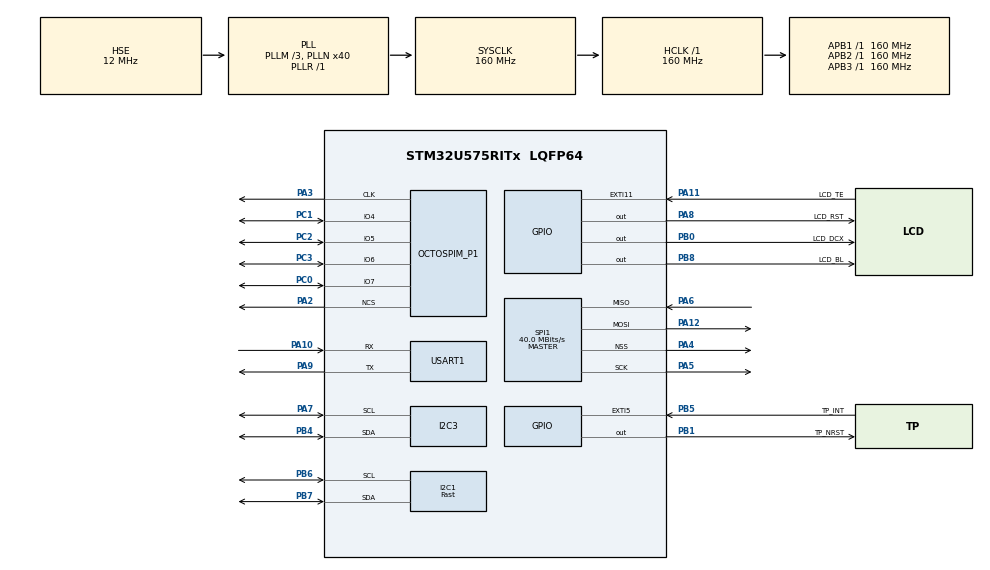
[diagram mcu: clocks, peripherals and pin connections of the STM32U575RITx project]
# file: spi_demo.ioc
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CORTEX_M33_NS.userName=CORTEX_M33
I2C1.I2C_Speed_Mode=I2C_Fast
I2C1.Timing=0x00F07BFF
I2C3.Timing=0x30909DEC
Mcu.Family=STM32U5
Mcu.Name=STM32U575RITx
Mcu.Package=LQFP64
NVIC.EXTI11_IRQn=true\:5\:0\:false\:false\:true\:true\:true\:true
NVIC.EXTI5_IRQn=true\:0\:0\:false\:false\:true\:true\:true\:true
NVIC.PriorityGroup=NVIC_PRIORITYGROUP_4
NVIC.TIM6_IRQn=true\:2\:0\:true\:false\:true\:false\:true\:true
NVIC.TimeBase=TIM6_IRQn
NVIC.TimeBaseIP=TIM6
PA10.Mode=Asynchronous
PA10.Signal=USART1_RX
PA11.GPIO_Label=LCD_TE
PA11.GPIO_ModeDefaultEXTI=GPIO_MODE_IT_FALLING
PA11.GPIO_PuPd=GPIO_PULLUP
PA11.Signal=GPXTI11
PA12.GPIO_Speed=GPIO_SPEED_FREQ_VERY_HIGH
PA12.Mode=Full_Duplex_Master
PA12.Signal=SPI1_MOSI
PA13\ (JTMS/SWDIO).Mode=Serial_Wire
PA13\ (JTMS/SWDIO).Signal=DEBUG_JTMS-SWDIO
PA14\ (JTCK/SWCLK).Mode=Serial_Wire
PA14\ (JTCK/SWCLK).Signal=DEBUG_JTCK-SWCLK
PA2.Mode=OCTOSPI1_Port1_NCS
PA2.Signal=OCTOSPIM_P1_NCS
PA3.Mode=O1_P1_CLK
PA3.Signal=OCTOSPIM_P1_CLK
PA4.Mode=NSS_Signal_Hard_Output
PA4.Signal=SPI1_NSS
PA5.GPIO_Speed=GPIO_SPEED_FREQ_VERY_HIGH
PA5.Mode=Full_Duplex_Master
PA5.Signal=SPI1_SCK
PA6.GPIO_Speed=GPIO_SPEED_FREQ_VERY_HIGH
PA6.Mode=Full_Duplex_Master
PA6.Signal=SPI1_MISO
PA7.Mode=I2C
PA7.Signal=I2C3_SCL
PA8.GPIO_Label=LCD_RST
PA8.Signal=GPIO_Output
PA9.Mode=Asynchronous
PA9.Signal=USART1_TX
PB0.GPIO_Label=LCD_DCX
PB0.Signal=GPIO_Output
PB1.GPIO_Label=TP_NRST
PB1.Signal=GPIO_Output
PB4\ (NJTRST).Mode=I2C
PB4\ (NJTRST).Signal=I2C3_SDA
PB5.GPIO_Label=TP_INT
PB5.GPIO_ModeDefaultEXTI=GPIO_MODE_IT_FALLING
PB5.GPIO_PuPd=GPIO_PULLUP
PB5.Signal=GPXTI5
PB6.Mode=I2C
PB6.Signal=I2C1_SCL
PB7.Mode=I2C
PB7.Signal=I2C1_SDA
PB8.GPIO_Label=LCD_BL
PB8.Signal=GPIO_Output
PC0.Mode=OCTOSPI1_IOL_Port1H
PC0.Signal=OCTOSPIM_P1_IO7
PC1.Mode=OCTOSPI1_IOL_Port1H
PC1.Signal=OCTOSPIM_P1_IO4
PC14-OSC32_IN\ (PC14).Mode=LSE-External-Oscillator-for-RTC
PC14-OSC32_IN\ (PC14).Signal=RCC_OSC32_IN
PC15-OSC32_OUT\ (PC15).Mode=LSE-External-Oscillator-for-RTC
PC15-OSC32_OUT\ (PC15).Signal=RCC_OSC32_OUT
PC2.Mode=OCTOSPI1_IOL_Port1H
PC2.Signal=OCTOSPIM_P1_IO5
PC3.Mode=OCTOSPI1_IOL_Port1H
PC3.Signal=OCTOSPIM_P1_IO6
PH0-OSC_IN\ (PH0).Mode=HSE-External-Oscillator
PH0-OSC_IN\ (PH0).Signal=RCC_OSC_IN
PH1-OSC_OUT\ (PH1).Mode=HSE-External-Oscillator
PH1-OSC_OUT\ (PH1).Signal=RCC_OSC_OUT
ProjectManager.HeapSize=0x200
ProjectManager.StackSize=0x400
ProjectManager.TargetToolchain=CMake
RCC.ADCFreq_Value=16000000
RCC.AHBFreq_Value=160000000
RCC.APB1Freq_Value=160000000
RCC.APB1TimFreq_Value=160000000
RCC.APB2Freq_Value=160000000
RCC.APB2TimFreq_Value=160000000
RCC.APB3Freq_Value=160000000
RCC.CortexFreq_Value=160000000
RCC.EPOD_VALUE=12000000
RCC.EnbaleCSS=true
RCC.HCLKFreq_Value=160000000
RCC.HSE_VALUE=12000000
RCC.HSI48_VALUE=48000000
RCC.HSI_VALUE=16000000
RCC.LSIDIV_VALUE=32000
RCC.MSI_VALUE=4000000
RCC.PLL1R=1
RCC.PLLFRACN=0
RCC.PLLM=3
RCC.PLLN=40
RCC.PLLSourceVirtual=RCC_PLLSOURCE_HSE
RCC.SYSCLKFreq_VALUE=160000000
RCC.SYSCLKSource=RCC_SYSCLKSOURCE_PLLCLK
RCC.USBFreq_Value=48000000
RCC.VCOOutputFreq_Value=160000000
SPI1.BaudRatePrescaler=SPI_BAUDRATEPRESCALER_4
SPI1.CalculateBaudRate=40.0 MBits/s
SPI1.DataSize=SPI_DATASIZE_8BIT
SPI1.Direction=SPI_DIRECTION_2LINES
SPI1.Mode=SPI_MODE_MASTER
SPI1.VirtualNSS=VM_NSSHARD
SPI1.VirtualType=VM_MASTER
STMicroelectronics.X-CUBE-TOUCHGFX.4.26.1.ApplicationCcGraphicsJjApplication=TouchGFXOoGenerator
STMicroelectronics.X-CUBE-TOUCHGFX.4.26.1.tgfx_custom_height=240
STMicroelectronics.X-CUBE-TOUCHGFX.4.26.1.tgfx_custom_width=240
STMicroelectronics.X-CUBE-TOUCHGFX.4.26.1_IsPackSelfContextualization=true
USART1.VirtualMode-Asynchronous=VM_ASYNC
VP_CRC_VS_CRC.Mode=CRC_Activate
VP_LPBAMQUEUE_VS_QUEUE.Mode=QUEUEMODE
VP_LPBAM_VS_SIG1.Mode=SmartRun
VP_LPBAM_VS_SIG4.Mode=LPDMA1
VP_MEMORYMAP_VS_MEMORYMAP.Mode=CurAppReg
VP_OCTOSPI1_VS_quad.Mode=quad_mode
VP_PWR_VS_SECSignals.Mode=Security/Privilege
VP_STMicroelectronics.X-CUBE-TOUCHGFX_VS_GraphicsJjApplication_4.26.1.Mode=GraphicsJjApplication
VP_SYS_VS_tim6.Mode=TIM6
board=custom

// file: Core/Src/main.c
/* USER CODE BEGIN Header */
/**
  ******************************************************************************
  * @file           : main.c
  * @brief          : Main program body
  ******************************************************************************
  * @attention
  *
  * Copyright (c) 2026 STMicroelectronics.
  * All rights reserved.
  *
  * This software is licensed under terms that can be found in the LICENSE file
  * in the root directory of this software component.
  * If no LICENSE file comes with this software, it is provided AS-IS.
  *
  ******************************************************************************
  */
/* USER CODE END Header */
#include "main.h"
#include "crc.h"
#include "i2c.h"
#include "octospi.h"
#include "spi.h"
#include "usart.h"
#include "gpio.h"
#include "app_touchgfx.h"

/* USER CODE BEGIN Includes */
#include "app_freertos.h"
/* USER CODE END Includes */

void SystemClock_Config(void);

/* USER CODE BEGIN 0 */

/**
  * @brief  Redirect printf output to USART1.
  * @param  file Output stream descriptor
  * @param  ptr  Data buffer
  * @param  len  Data length
  * @retval Number of transmitted bytes, or -1 on error
  */
int _write(int file, char *ptr, int len)
{
  (void)file;

  return App_UART_Write(ptr, len);
}

/* USER CODE END 0 */

int main(void)
{

  /* MCU Configuration--------------------------------------------------------*/

  /* Reset of all peripherals, Initializes the Flash interface and the Systick. */
  HAL_Init();

  /* Configure the system clock */
  SystemClock_Config();

  /* Initialize all configured peripherals */
  MX_GPIO_Init();
  MX_USART1_UART_Init();
  MX_SPI1_Init();
  MX_CRC_Init();
  MX_I2C1_Init();
  MX_I2C3_Init();
  MX_OCTOSPI1_Init();
  MX_TouchGFX_Init();
  /* USER CODE BEGIN 2 */
  /* All application work belongs to FreeRTOS tasks. Success never returns. */
  (void)App_FreeRTOS_Start();
  Error_Handler();
  /* USER CODE END 2 */

  /* Infinite loop */

  MX_TouchGFX_Process();
}

void SystemClock_Config(void)
{
  RCC_OscInitTypeDef RCC_OscInitStruct = {0};
  RCC_ClkInitTypeDef RCC_ClkInitStruct = {0};

  /** Configure the main internal regulator output voltage
  */
  if (HAL_PWREx_ControlVoltageScaling(PWR_REGULATOR_VOLTAGE_SCALE1) != HAL_OK)
  {
    Error_Handler();
  }

  /** Initializes the CPU, AHB and APB buses clocks
  */
  RCC_OscInitStruct.OscillatorType = RCC_OSCILLATORTYPE_HSE;
  RCC_OscInitStruct.HSEState = RCC_HSE_ON;
  RCC_OscInitStruct.PLL.PLLState = RCC_PLL_ON;
  RCC_OscInitStruct.PLL.PLLSource = RCC_PLLSOURCE_HSE;
  RCC_OscInitStruct.PLL.PLLMBOOST = RCC_PLLMBOOST_DIV1;
  RCC_OscInitStruct.PLL.PLLM = 3;
  RCC_OscInitStruct.PLL.PLLN = 40;
  RCC_OscInitStruct.PLL.PLLP = 2;
  RCC_OscInitStruct.PLL.PLLQ = 2;
  RCC_OscInitStruct.PLL.PLLR = 1;
  RCC_OscInitStruct.PLL.PLLRGE = RCC_PLLVCIRANGE_0;
  RCC_OscInitStruct.PLL.PLLFRACN = 0;
  if (HAL_RCC_OscConfig(&RCC_OscInitStruct) != HAL_OK)
  {
    Error_Handler();
  }

  /** Initializes the CPU, AHB and APB buses clocks
  */
  RCC_ClkInitStruct.ClockType = RCC_CLOCKTYPE_HCLK|RCC_CLOCKTYPE_SYSCLK
                              |RCC_CLOCKTYPE_PCLK1|RCC_CLOCKTYPE_PCLK2
                              |RCC_CLOCKTYPE_PCLK3;
  RCC_ClkInitStruct.SYSCLKSource = RCC_SYSCLKSOURCE_PLLCLK;
  RCC_ClkInitStruct.AHBCLKDivider = RCC_SYSCLK_DIV1;
  RCC_ClkInitStruct.APB1CLKDivider = RCC_HCLK_DIV1;
  RCC_ClkInitStruct.APB2CLKDivider = RCC_HCLK_DIV1;
  RCC_ClkInitStruct.APB3CLKDivider = RCC_HCLK_DIV1;

  if (HAL_RCC_ClockConfig(&RCC_ClkInitStruct, FLASH_LATENCY_4) != HAL_OK)
  {
    Error_Handler();
  }

  /** Enables the Clock Security System
  */
  HAL_RCC_EnableCSS();
}

void HAL_TIM_PeriodElapsedCallback(TIM_HandleTypeDef *htim)
{
  if (htim->Instance == TIM6)
  {
    HAL_IncTick();
  }
}

void Error_Handler(void)
{
  __disable_irq();
  while (1)
  {
  }
}
